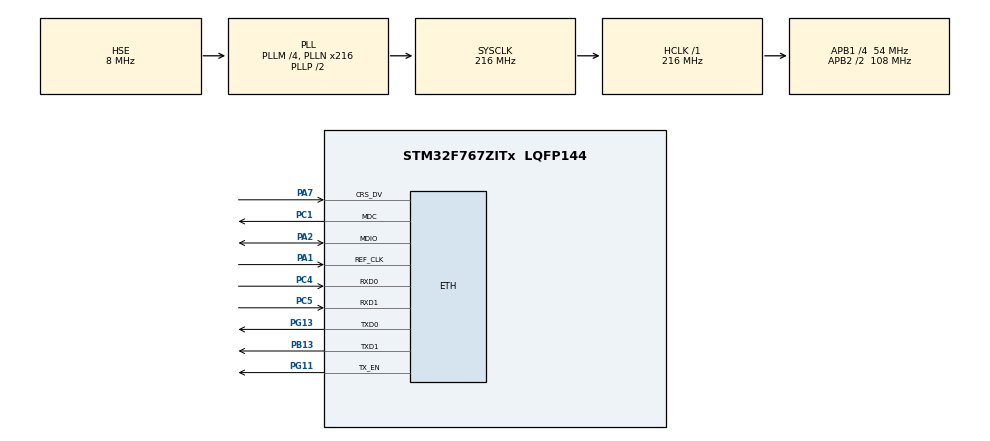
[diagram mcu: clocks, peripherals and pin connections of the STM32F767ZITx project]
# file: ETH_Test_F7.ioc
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CORTEX_M7.AccessPermission-Cortex_Memory_Protection_Unit_Region0_Settings=MPU_REGION_FULL_ACCESS
CORTEX_M7.AccessPermission-Cortex_Memory_Protection_Unit_Region1_Settings=MPU_REGION_FULL_ACCESS
CORTEX_M7.BaseAddress-Cortex_Memory_Protection_Unit_Region0_Settings=( uint32_t )&__ETH_BUFFERS_START
CORTEX_M7.BaseAddress-Cortex_Memory_Protection_Unit_Region1_Settings=( uint32_t )&__ETH_DESCRIPTORS_START
CORTEX_M7.CPU_DCache=Enabled
CORTEX_M7.CPU_ICache=Enabled
CORTEX_M7.DisableExec-Cortex_Memory_Protection_Unit_Region0_Settings=MPU_INSTRUCTION_ACCESS_DISABLE
CORTEX_M7.DisableExec-Cortex_Memory_Protection_Unit_Region1_Settings=MPU_INSTRUCTION_ACCESS_DISABLE
CORTEX_M7.Enable-Cortex_Memory_Protection_Unit_Region0_Settings=MPU_REGION_ENABLE
CORTEX_M7.Enable-Cortex_Memory_Protection_Unit_Region1_Settings=MPU_REGION_ENABLE
CORTEX_M7.Enable-Cortex_Memory_Protection_Unit_Region2_Settings=__NULL
CORTEX_M7.IsBufferable-Cortex_Memory_Protection_Unit_Region1_Settings=MPU_ACCESS_BUFFERABLE
CORTEX_M7.MPU_Control=MPU_PRIVILEGED_DEFAULT
CORTEX_M7.Size-Cortex_Memory_Protection_Unit_Region0_Settings=MPU_REGION_SIZE_128KB
CORTEX_M7.Size-Cortex_Memory_Protection_Unit_Region1_Settings=MPU_REGION_SIZE_1KB
CORTEX_M7.TypeExtField-Cortex_Memory_Protection_Unit_Region0_Settings=MPU_TEX_LEVEL1
CORTEX_M7.TypeExtField-Cortex_Memory_Protection_Unit_Region1_Settings=MPU_TEX_LEVEL0
ETH.MediaInterface=HAL_ETH_RMII_MODE
ETH.RxMode=ETH_RXINTERRUPT_MODE
Mcu.Family=STM32F7
Mcu.Name=STM32F767ZITx
Mcu.Package=LQFP144
NVIC.ETH_IRQn=true\:5\:0\:true\:false\:false\:false\:true\:true
NVIC.PriorityGroup=NVIC_PRIORITYGROUP_4
NVIC.TIM6_DAC_IRQn=true\:15\:0\:false\:false\:true\:false\:true\:true
NVIC.TimeBase=TIM6_DAC_IRQn
NVIC.TimeBaseIP=TIM6
PA1.Mode=RMII
PA1.Signal=ETH_REF_CLK
PA2.GPIO_Speed=GPIO_SPEED_FREQ_VERY_HIGH
PA2.Mode=RMII
PA2.Signal=ETH_MDIO
PA7.Mode=RMII
PA7.Signal=ETH_CRS_DV
PB13.Mode=RMII
PB13.Signal=ETH_TXD1
PC1.GPIO_Speed=GPIO_SPEED_FREQ_HIGH
PC1.Mode=RMII
PC1.Signal=ETH_MDC
PC4.Mode=RMII
PC4.Signal=ETH_RXD0
PC5.Mode=RMII
PC5.Signal=ETH_RXD1
PG11.Mode=RMII
PG11.Signal=ETH_TX_EN
PG13.Mode=RMII
PG13.Signal=ETH_TXD0
PH0/OSC_IN.Mode=HSE-External-Clock-Source
PH0/OSC_IN.Signal=RCC_OSC_IN
PH1/OSC_OUT.Mode=HSE-External-Clock-Source
PH1/OSC_OUT.Signal=RCC_OSC_OUT
ProjectManager.HeapSize=0x400
ProjectManager.StackSize=0x800
ProjectManager.TargetToolchain=STM32CubeIDE
RCC.48MHZClocksFreq_Value=24000000
RCC.AHBFreq_Value=216000000
RCC.APB1CLKDivider=RCC_HCLK_DIV4
RCC.APB1Freq_Value=54000000
RCC.APB1TimFreq_Value=108000000
RCC.APB2CLKDivider=RCC_HCLK_DIV2
RCC.APB2Freq_Value=108000000
RCC.APB2TimFreq_Value=216000000
RCC.CortexFreq_Value=216000000
RCC.HCLKFreq_Value=216000000
RCC.HSE_VALUE=8000000
RCC.HSI_VALUE=16000000
RCC.LSE_VALUE=32768
RCC.PLLM=4
RCC.PLLMUL=RCC_PLL_MUL9
RCC.PLLN=216
RCC.PLLSourceVirtual=RCC_PLLSOURCE_HSE
RCC.PRESCALERUSB=RCC_USBCLKSOURCE_PLL_DIV1_5
RCC.SYSCLKFreq_VALUE=216000000
RCC.SYSCLKSource=RCC_SYSCLKSOURCE_PLLCLK
RCC.SYSCLKSourceVirtual=RCC_SYSCLKSOURCE_PLLCLK
RCC.USBFreq_Value=216000000
RCC.VCOOutputFreq_Value=432000000
VP_SYS_VS_tim6.Mode=TIM6
board=NUCLEO-F767ZI

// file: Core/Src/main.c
/* USER CODE BEGIN Header */
/**
  ******************************************************************************
  * @file           : main.c
  * @brief          : Main program body
  ******************************************************************************
  * @attention
  *
  * Copyright (c) 2024 STMicroelectronics.
  * All rights reserved.
  *
  * This software is licensed under terms that can be found in the LICENSE file
  * in the root directory of this software component.
  * If no LICENSE file comes with this software, it is provided AS-IS.
  *
  ******************************************************************************
  */
/* USER CODE END Header */
#include "main.h"
#include "gpio.h"

/* USER CODE BEGIN Includes */
#include <FreeRTOS.h>
#include <task.h>
/* USER CODE END Includes */

void SystemClock_Config(void);
static void MPU_Config(void);

/* USER CODE BEGIN 0 */
extern void CommsTask_vInit();
/* USER CODE END 0 */

int main(void)
{

  /* MPU Configuration--------------------------------------------------------*/
  MPU_Config();
/* Enable the CPU Cache */

  /* Enable I-Cache---------------------------------------------------------*/
  SCB_EnableICache();

  /* Enable D-Cache---------------------------------------------------------*/
  SCB_EnableDCache();

  /* MCU Configuration--------------------------------------------------------*/

  /* Reset of all peripherals, Initializes the Flash interface and the Systick. */
  HAL_Init();

  /* Configure the system clock */
  SystemClock_Config();

  /* Initialize all configured peripherals */
  MX_GPIO_Init();
  /* USER CODE BEGIN 2 */
  CommsTask_vInit();
  vTaskStartScheduler();
  /* USER CODE END 2 */

  /* Infinite loop */
  while (1)
  {

  }
}

void SystemClock_Config(void)
{
  RCC_OscInitTypeDef RCC_OscInitStruct = {0};
  RCC_ClkInitTypeDef RCC_ClkInitStruct = {0};

  /** Configure the main internal regulator output voltage
  */
  __HAL_RCC_PWR_CLK_ENABLE();
  __HAL_PWR_VOLTAGESCALING_CONFIG(PWR_REGULATOR_VOLTAGE_SCALE1);

  /** Initializes the RCC Oscillators according to the specified parameters
  * in the RCC_OscInitTypeDef structure.
  */
  RCC_OscInitStruct.OscillatorType = RCC_OSCILLATORTYPE_HSE;
  RCC_OscInitStruct.HSEState = RCC_HSE_BYPASS;
  RCC_OscInitStruct.PLL.PLLState = RCC_PLL_ON;
  RCC_OscInitStruct.PLL.PLLSource = RCC_PLLSOURCE_HSE;
  RCC_OscInitStruct.PLL.PLLM = 4;
  RCC_OscInitStruct.PLL.PLLN = 216;
  RCC_OscInitStruct.PLL.PLLP = RCC_PLLP_DIV2;
  RCC_OscInitStruct.PLL.PLLQ = 2;
  RCC_OscInitStruct.PLL.PLLR = 2;
  if (HAL_RCC_OscConfig(&RCC_OscInitStruct) != HAL_OK)
  {
    Error_Handler();
  }

  /** Activate the Over-Drive mode
  */
  if (HAL_PWREx_EnableOverDrive() != HAL_OK)
  {
    Error_Handler();
  }

  /** Initializes the CPU, AHB and APB buses clocks
  */
  RCC_ClkInitStruct.ClockType = RCC_CLOCKTYPE_HCLK|RCC_CLOCKTYPE_SYSCLK
                              |RCC_CLOCKTYPE_PCLK1|RCC_CLOCKTYPE_PCLK2;
  RCC_ClkInitStruct.SYSCLKSource = RCC_SYSCLKSOURCE_PLLCLK;
  RCC_ClkInitStruct.AHBCLKDivider = RCC_SYSCLK_DIV1;
  RCC_ClkInitStruct.APB1CLKDivider = RCC_HCLK_DIV4;
  RCC_ClkInitStruct.APB2CLKDivider = RCC_HCLK_DIV2;

  if (HAL_RCC_ClockConfig(&RCC_ClkInitStruct, FLASH_LATENCY_7) != HAL_OK)
  {
    Error_Handler();
  }
}

/* USER CODE BEGIN 4 */
extern uint8_t __ETH_BUFFERS_START, __ETH_DESCRIPTORS_START;
/* USER CODE END 4 */

/* MPU Configuration */

void MPU_Config(void)
{
  MPU_Region_InitTypeDef MPU_InitStruct = {0};

  /* Disables the MPU */
  HAL_MPU_Disable();

  /** Initializes and configures the Region and the memory to be protected
  */
  MPU_InitStruct.Enable = MPU_REGION_ENABLE;
  MPU_InitStruct.Number = MPU_REGION_NUMBER0;
  MPU_InitStruct.BaseAddress = ( uint32_t )&__ETH_BUFFERS_START;
  MPU_InitStruct.Size = MPU_REGION_SIZE_64KB;
  MPU_InitStruct.SubRegionDisable = 0x0;
  MPU_InitStruct.TypeExtField = MPU_TEX_LEVEL1;
  MPU_InitStruct.AccessPermission = MPU_REGION_FULL_ACCESS;
  MPU_InitStruct.DisableExec = MPU_INSTRUCTION_ACCESS_DISABLE;
  MPU_InitStruct.IsShareable = MPU_ACCESS_NOT_SHAREABLE;
  MPU_InitStruct.IsCacheable = MPU_ACCESS_NOT_CACHEABLE;
  MPU_InitStruct.IsBufferable = MPU_ACCESS_NOT_BUFFERABLE;

  HAL_MPU_ConfigRegion(&MPU_InitStruct);

  /** Initializes and configures the Region and the memory to be protected
  */
  MPU_InitStruct.Enable = MPU_REGION_ENABLE;
  MPU_InitStruct.Number = MPU_REGION_NUMBER1;
  MPU_InitStruct.BaseAddress = ( uint32_t )&__ETH_DESCRIPTORS_START;
  MPU_InitStruct.Size = MPU_REGION_SIZE_1KB;
  MPU_InitStruct.SubRegionDisable = 0x0;
  MPU_InitStruct.TypeExtField = MPU_TEX_LEVEL0;
  MPU_InitStruct.AccessPermission = MPU_REGION_FULL_ACCESS;
  MPU_InitStruct.DisableExec = MPU_INSTRUCTION_ACCESS_DISABLE;
  MPU_InitStruct.IsShareable = MPU_ACCESS_SHAREABLE;
  MPU_InitStruct.IsCacheable = MPU_ACCESS_NOT_CACHEABLE;
  MPU_InitStruct.IsBufferable = MPU_ACCESS_BUFFERABLE;

  HAL_MPU_ConfigRegion(&MPU_InitStruct);
  /* Enables the MPU */
  HAL_MPU_Enable(MPU_PRIVILEGED_DEFAULT);

}

void HAL_TIM_PeriodElapsedCallback(TIM_HandleTypeDef *htim)
{
  if (htim->Instance == TIM6) {
    HAL_IncTick();
  }
}

void Error_Handler(void)
{
  __disable_irq();
  while (1)
  {
  }
}

#ifdef  USE_FULL_ASSERT
/**
  * @brief  Reports the name of the source file and the source line number
  *         where the assert_param error has occurred.
  * @param  file: pointer to the source file name
  * @param  line: assert_param error line source number
  * @retval None
  */
void assert_failed(uint8_t *file, uint32_t line)
{
  /* USER CODE BEGIN 6 */
  /* User can add his own implementation to report the file name and line number,
     ex: printf("Wrong parameters value: file %s on line %d\r\n", file, line) */
	Error_Handler();
  /* USER CODE END 6 */
}
#endif /* USE_FULL_ASSERT */
